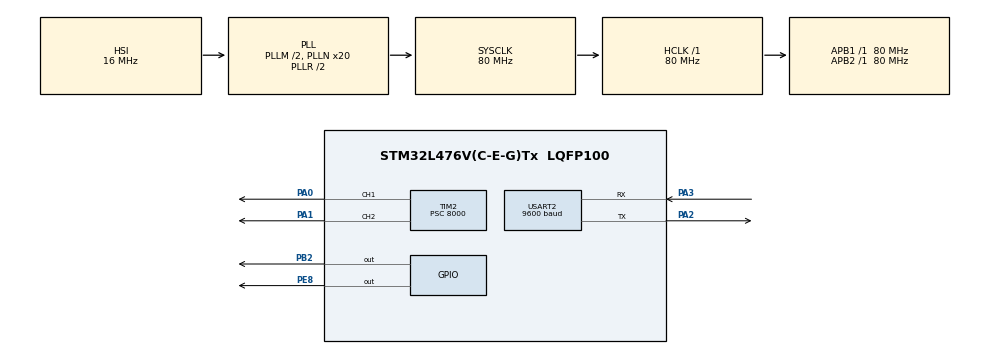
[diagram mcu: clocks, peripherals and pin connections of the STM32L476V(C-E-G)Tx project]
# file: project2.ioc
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Mcu.Family=STM32L4
Mcu.Name=STM32L476V(C-E-G)Tx
Mcu.Package=LQFP100
NVIC.PriorityGroup=NVIC_PRIORITYGROUP_4
PA0.Signal=S_TIM2_CH1
PA1.Signal=S_TIM2_CH2
PA2.Mode=Asynchronous
PA2.Signal=USART2_TX
PA3.Mode=Asynchronous
PA3.Signal=USART2_RX
PB2.Signal=GPIO_Output
PE8.Signal=GPIO_Output
ProjectManager.HeapSize=0x200
ProjectManager.StackSize=0x400
ProjectManager.TargetToolchain=MDK-ARM V5
RCC.ADCFreq_Value=32000000
RCC.AHBFreq_Value=80000000
RCC.APB1Freq_Value=80000000
RCC.APB1TimFreq_Value=80000000
RCC.APB2Freq_Value=80000000
RCC.APB2TimFreq_Value=80000000
RCC.CortexFreq_Value=80000000
RCC.HCLKFreq_Value=80000000
RCC.HSE_VALUE=8000000
RCC.HSI_VALUE=16000000
RCC.LSE_VALUE=32768
RCC.MSI_VALUE=4000000
RCC.PLLM=2
RCC.PLLN=20
RCC.PLLSourceVirtual=RCC_PLLSOURCE_HSI
RCC.SYSCLKFreq_VALUE=80000000
RCC.SYSCLKSource=RCC_SYSCLKSOURCE_PLLCLK
RCC.USBFreq_Value=32000000
RCC.VCOOutputFreq_Value=160000000
SH.S_TIM2_CH1.0=TIM2_CH1,PWM Generation1 CH1
SH.S_TIM2_CH2.0=TIM2_CH2,PWM Generation2 CH2
TIM2.AutoReloadPreload=TIM_AUTORELOAD_PRELOAD_ENABLE
TIM2.Channel-PWM\ Generation1\ CH1=TIM_CHANNEL_1
TIM2.Channel-PWM\ Generation2\ CH2=TIM_CHANNEL_2
TIM2.Period=200
TIM2.Prescaler=8000
TIM3.AutoReloadPreload=TIM_AUTORELOAD_PRELOAD_ENABLE
TIM3.Period=1000
TIM3.Prescaler=8000
TIM3.TIM_MasterOutputTrigger=TIM_TRGO_UPDATE
USART2.BaudRate=9600
USART2.VirtualMode-Asynchronous=VM_ASYNC
VP_TIM2_VS_ClockSourceINT.Mode=Internal
VP_TIM3_VS_ClockSourceINT.Mode=Internal
board=custom

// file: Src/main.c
/* USER CODE BEGIN Header */
/**
  ******************************************************************************
  * @file           : main.c
  * @brief          : Main program body
  ******************************************************************************
  ** This notice applies to any and all portions of this file
  * that are not between comment pairs USER CODE BEGIN and
  * USER CODE END. Other portions of this file, whether
  * inserted by the user or by software development tools
  * are owned by their respective copyright owners.
  *
  * COPYRIGHT(c) 2019 STMicroelectronics
  *
  * Redistribution and use in source and binary forms, with or without modification,
  * are permitted provided that the following conditions are met:
  *   1. Redistributions of source code must retain the above copyright notice,
  *      this list of conditions and the following disclaimer.
  *   2. Redistributions in binary form must reproduce the above copyright notice,
  *      this list of conditions and the following disclaimer in the documentation
  *      and/or other materials provided with the distribution.
  *   3. Neither the name of STMicroelectronics nor the names of its contributors
  *      may be used to endorse or promote products derived from this software
  *      without specific prior written permission.
  *
  * THIS SOFTWARE IS PROVIDED BY THE COPYRIGHT HOLDERS AND CONTRIBUTORS "AS IS"
  * AND ANY EXPRESS OR IMPLIED WARRANTIES, INCLUDING, BUT NOT LIMITED TO, THE
  * IMPLIED WARRANTIES OF MERCHANTABILITY AND FITNESS FOR A PARTICULAR PURPOSE ARE
  * DISCLAIMED. IN NO EVENT SHALL THE COPYRIGHT HOLDER OR CONTRIBUTORS BE LIABLE
  * FOR ANY DIRECT, INDIRECT, INCIDENTAL, SPECIAL, EXEMPLARY, OR CONSEQUENTIAL
  * DAMAGES (INCLUDING, BUT NOT LIMITED TO, PROCUREMENT OF SUBSTITUTE GOODS OR
  * SERVICES; LOSS OF USE, DATA, OR PROFITS; OR BUSINESS INTERRUPTION) HOWEVER
  * CAUSED AND ON ANY THEORY OF LIABILITY, WHETHER IN CONTRACT, STRICT LIABILITY,
  * OR TORT (INCLUDING NEGLIGENCE OR OTHERWISE) ARISING IN ANY WAY OUT OF THE USE
  * OF THIS SOFTWARE, EVEN IF ADVISED OF THE POSSIBILITY OF SUCH DAMAGE.
  *
  ******************************************************************************
  */
/* USER CODE END Header */

#include "main.h"

/* USER CODE BEGIN Includes */
#include "UART.h"
#include <string.h>
/* USER CODE END Includes */

TIM_HandleTypeDef htim2;
TIM_HandleTypeDef htim3;

UART_HandleTypeDef huart2;

/* USER CODE BEGIN PV */
typedef unsigned char uint8_t;
/* USER CODE END PV */

void SystemClock_Config(void);
static void MX_GPIO_Init(void);
static void MX_TIM2_Init(void);
static void MX_TIM3_Init(void);
static void MX_USART2_UART_Init(void);

/* USER CODE BEGIN 0 */
	char test[] = "Hello World\r\n";

/* USER CODE END 0 */

int main(void)
{

  /* MCU Configuration--------------------------------------------------------*/

  /* Reset of all peripherals, Initializes the Flash interface and the Systick. */
  HAL_Init();

  /* Configure the system clock */
  SystemClock_Config();

  /* Initialize all configured peripherals */
  MX_GPIO_Init();
  MX_TIM2_Init();
  MX_TIM3_Init();
  MX_USART2_UART_Init();

  /* Infinite loop */
  /* USER CODE BEGIN WHILE */
  while (1)
  {
		USART_Write(USART2, (uint8_t *)test, strlen(test));
    /* USER CODE END WHILE */

  }
}

void SystemClock_Config(void)
{
  RCC_OscInitTypeDef RCC_OscInitStruct = {0};
  RCC_ClkInitTypeDef RCC_ClkInitStruct = {0};
  RCC_PeriphCLKInitTypeDef PeriphClkInit = {0};

  /**Initializes the CPU, AHB and APB busses clocks
  */
  RCC_OscInitStruct.OscillatorType = RCC_OSCILLATORTYPE_HSI;
  RCC_OscInitStruct.HSIState = RCC_HSI_ON;
  RCC_OscInitStruct.HSICalibrationValue = RCC_HSICALIBRATION_DEFAULT;
  RCC_OscInitStruct.PLL.PLLState = RCC_PLL_ON;
  RCC_OscInitStruct.PLL.PLLSource = RCC_PLLSOURCE_HSI;
  RCC_OscInitStruct.PLL.PLLM = 2;
  RCC_OscInitStruct.PLL.PLLN = 20;
  RCC_OscInitStruct.PLL.PLLP = RCC_PLLP_DIV7;
  RCC_OscInitStruct.PLL.PLLQ = RCC_PLLQ_DIV2;
  RCC_OscInitStruct.PLL.PLLR = RCC_PLLR_DIV2;
  if (HAL_RCC_OscConfig(&RCC_OscInitStruct) != HAL_OK)
  {
    Error_Handler();
  }
  /**Initializes the CPU, AHB and APB busses clocks
  */
  RCC_ClkInitStruct.ClockType = RCC_CLOCKTYPE_HCLK|RCC_CLOCKTYPE_SYSCLK
                              |RCC_CLOCKTYPE_PCLK1|RCC_CLOCKTYPE_PCLK2;
  RCC_ClkInitStruct.SYSCLKSource = RCC_SYSCLKSOURCE_PLLCLK;
  RCC_ClkInitStruct.AHBCLKDivider = RCC_SYSCLK_DIV1;
  RCC_ClkInitStruct.APB1CLKDivider = RCC_HCLK_DIV1;
  RCC_ClkInitStruct.APB2CLKDivider = RCC_HCLK_DIV1;

  if (HAL_RCC_ClockConfig(&RCC_ClkInitStruct, FLASH_LATENCY_4) != HAL_OK)
  {
    Error_Handler();
  }
  PeriphClkInit.PeriphClockSelection = RCC_PERIPHCLK_USART2;
  PeriphClkInit.Usart2ClockSelection = RCC_USART2CLKSOURCE_PCLK1;
  if (HAL_RCCEx_PeriphCLKConfig(&PeriphClkInit) != HAL_OK)
  {
    Error_Handler();
  }
  /**Configure the main internal regulator output voltage
  */
  if (HAL_PWREx_ControlVoltageScaling(PWR_REGULATOR_VOLTAGE_SCALE1) != HAL_OK)
  {
    Error_Handler();
  }
}

static void MX_TIM2_Init(void)
{

  TIM_ClockConfigTypeDef sClockSourceConfig = {0};
  TIM_MasterConfigTypeDef sMasterConfig = {0};
  TIM_OC_InitTypeDef sConfigOC = {0};

  htim2.Instance = TIM2;
  htim2.Init.Prescaler = 8000;
  htim2.Init.CounterMode = TIM_COUNTERMODE_UP;
  htim2.Init.Period = 200;
  htim2.Init.ClockDivision = TIM_CLOCKDIVISION_DIV1;
  htim2.Init.AutoReloadPreload = TIM_AUTORELOAD_PRELOAD_ENABLE;
  if (HAL_TIM_Base_Init(&htim2) != HAL_OK)
  {
    Error_Handler();
  }
  sClockSourceConfig.ClockSource = TIM_CLOCKSOURCE_INTERNAL;
  if (HAL_TIM_ConfigClockSource(&htim2, &sClockSourceConfig) != HAL_OK)
  {
    Error_Handler();
  }
  if (HAL_TIM_PWM_Init(&htim2) != HAL_OK)
  {
    Error_Handler();
  }
  sMasterConfig.MasterOutputTrigger = TIM_TRGO_RESET;
  sMasterConfig.MasterSlaveMode = TIM_MASTERSLAVEMODE_DISABLE;
  if (HAL_TIMEx_MasterConfigSynchronization(&htim2, &sMasterConfig) != HAL_OK)
  {
    Error_Handler();
  }
  sConfigOC.OCMode = TIM_OCMODE_PWM1;
  sConfigOC.Pulse = 0;
  sConfigOC.OCPolarity = TIM_OCPOLARITY_HIGH;
  sConfigOC.OCFastMode = TIM_OCFAST_DISABLE;
  if (HAL_TIM_PWM_ConfigChannel(&htim2, &sConfigOC, TIM_CHANNEL_1) != HAL_OK)
  {
    Error_Handler();
  }
  if (HAL_TIM_PWM_ConfigChannel(&htim2, &sConfigOC, TIM_CHANNEL_2) != HAL_OK)
  {
    Error_Handler();
  }
  HAL_TIM_MspPostInit(&htim2);

}

static void MX_TIM3_Init(void)
{

  TIM_ClockConfigTypeDef sClockSourceConfig = {0};
  TIM_MasterConfigTypeDef sMasterConfig = {0};

  htim3.Instance = TIM3;
  htim3.Init.Prescaler = 8000;
  htim3.Init.CounterMode = TIM_COUNTERMODE_UP;
  htim3.Init.Period = 1000;
  htim3.Init.ClockDivision = TIM_CLOCKDIVISION_DIV1;
  htim3.Init.AutoReloadPreload = TIM_AUTORELOAD_PRELOAD_ENABLE;
  if (HAL_TIM_Base_Init(&htim3) != HAL_OK)
  {
    Error_Handler();
  }
  sClockSourceConfig.ClockSource = TIM_CLOCKSOURCE_INTERNAL;
  if (HAL_TIM_ConfigClockSource(&htim3, &sClockSourceConfig) != HAL_OK)
  {
    Error_Handler();
  }
  sMasterConfig.MasterOutputTrigger = TIM_TRGO_UPDATE;
  sMasterConfig.MasterSlaveMode = TIM_MASTERSLAVEMODE_DISABLE;
  if (HAL_TIMEx_MasterConfigSynchronization(&htim3, &sMasterConfig) != HAL_OK)
  {
    Error_Handler();
  }

}

static void MX_USART2_UART_Init(void)
{

  huart2.Instance = USART2;
  huart2.Init.BaudRate = 9600;
  huart2.Init.WordLength = UART_WORDLENGTH_8B;
  huart2.Init.StopBits = UART_STOPBITS_1;
  huart2.Init.Parity = UART_PARITY_NONE;
  huart2.Init.Mode = UART_MODE_TX_RX;
  huart2.Init.HwFlowCtl = UART_HWCONTROL_NONE;
  huart2.Init.OverSampling = UART_OVERSAMPLING_16;
  huart2.Init.OneBitSampling = UART_ONE_BIT_SAMPLE_DISABLE;
  huart2.AdvancedInit.AdvFeatureInit = UART_ADVFEATURE_NO_INIT;
  if (HAL_UART_Init(&huart2) != HAL_OK)
  {
    Error_Handler();
  }

}

static void MX_GPIO_Init(void)
{
  GPIO_InitTypeDef GPIO_InitStruct = {0};

  /* GPIO Ports Clock Enable */
  __HAL_RCC_GPIOA_CLK_ENABLE();
  __HAL_RCC_GPIOB_CLK_ENABLE();
  __HAL_RCC_GPIOE_CLK_ENABLE();

  /*Configure GPIO pin Output Level */
  HAL_GPIO_WritePin(GPIOB, GPIO_PIN_2, GPIO_PIN_RESET);

  /*Configure GPIO pin Output Level */
  HAL_GPIO_WritePin(GPIOE, GPIO_PIN_8, GPIO_PIN_RESET);

  /*Configure GPIO pin : PB2 */
  GPIO_InitStruct.Pin = GPIO_PIN_2;
  GPIO_InitStruct.Mode = GPIO_MODE_OUTPUT_PP;
  GPIO_InitStruct.Pull = GPIO_NOPULL;
  GPIO_InitStruct.Speed = GPIO_SPEED_FREQ_LOW;
  HAL_GPIO_Init(GPIOB, &GPIO_InitStruct);

  /*Configure GPIO pin : PE8 */
  GPIO_InitStruct.Pin = GPIO_PIN_8;
  GPIO_InitStruct.Mode = GPIO_MODE_OUTPUT_PP;
  GPIO_InitStruct.Pull = GPIO_NOPULL;
  GPIO_InitStruct.Speed = GPIO_SPEED_FREQ_LOW;
  HAL_GPIO_Init(GPIOE, &GPIO_InitStruct);

}

void Error_Handler(void)
{
}

/************************ (C) COPYRIGHT STMicroelectronics *****END OF FILE****/
